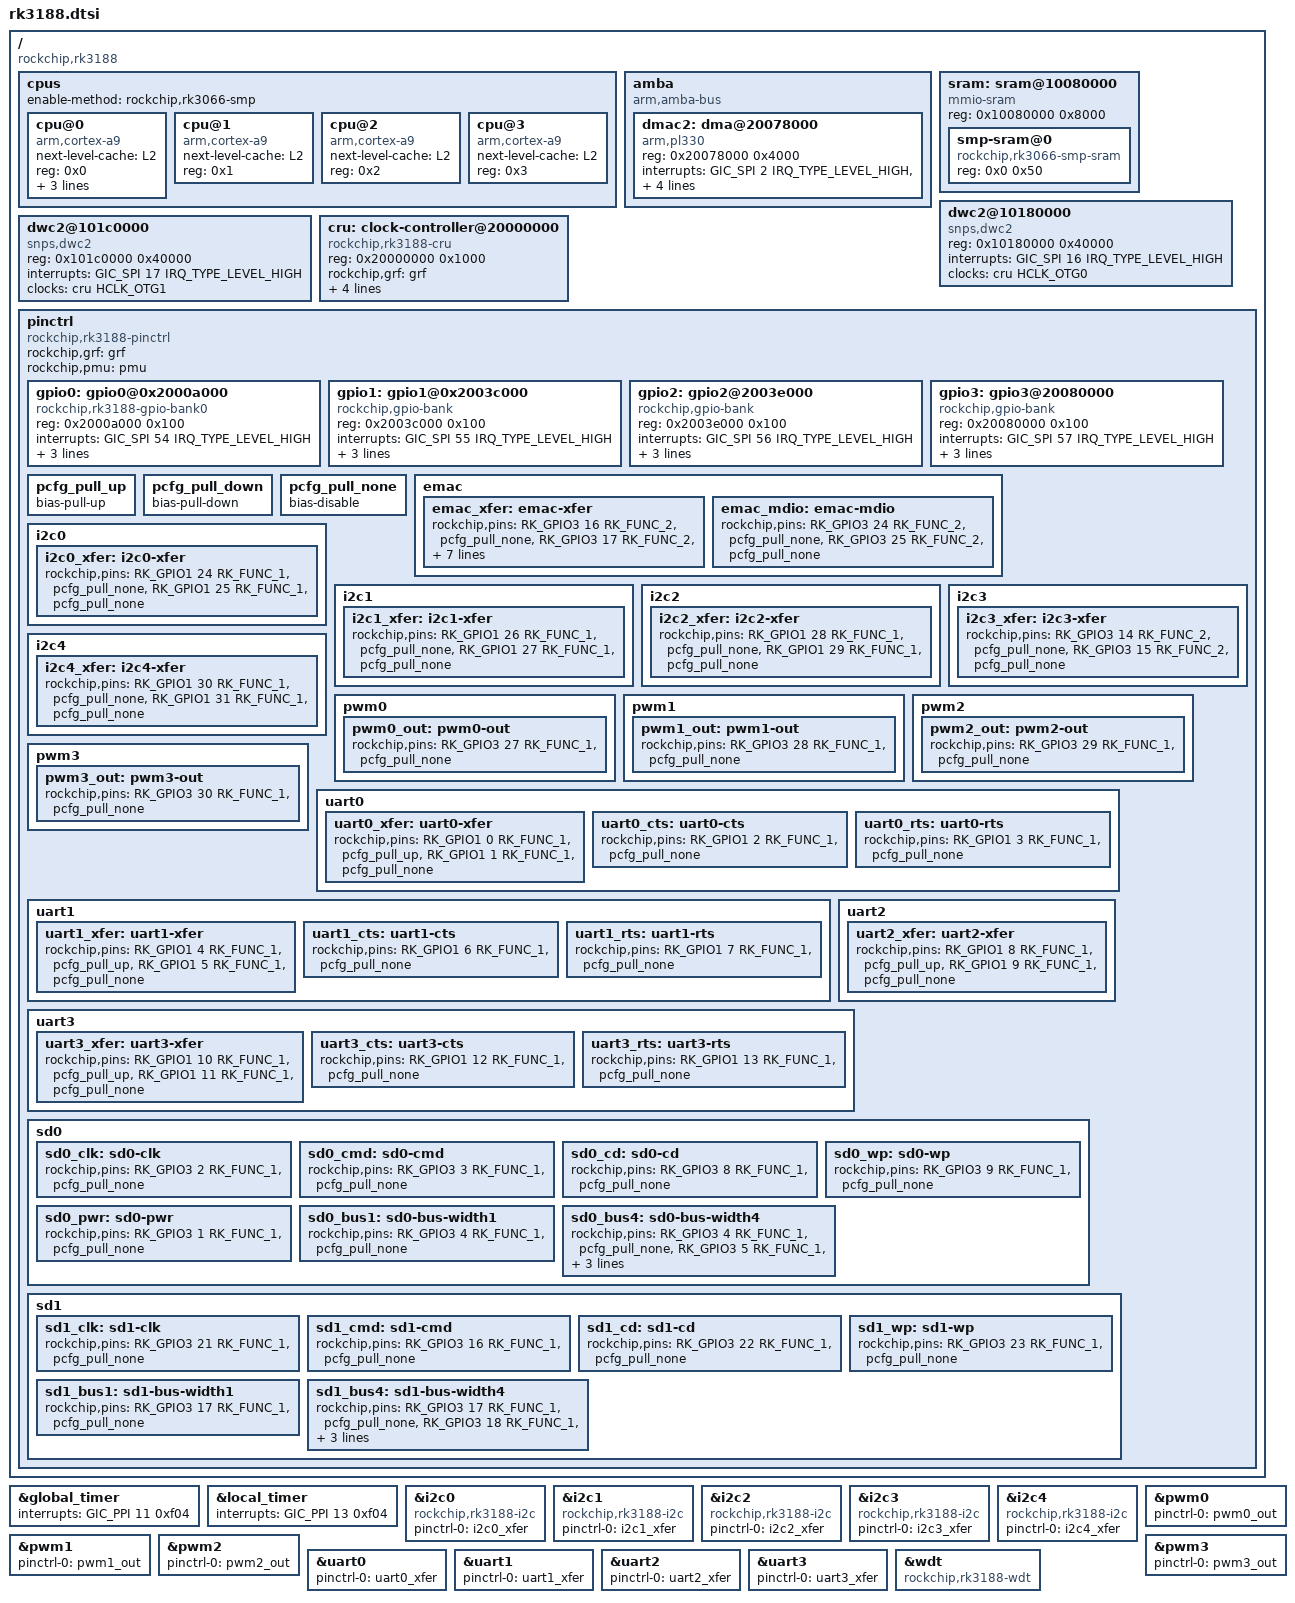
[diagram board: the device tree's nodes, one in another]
/*
 * Copyright (c) 2013 MundoReader S.L.
 * Author: Heiko Stuebner <heiko@sntech.de>
 *
 * This program is free software; you can redistribute it and/or modify
 * it under the terms of the GNU General Public License as published by
 * the Free Software Foundation; either version 2 of the License, or
 * (at your option) any later version.
 *
 * This program is distributed in the hope that it will be useful,
 * but WITHOUT ANY WARRANTY; without even the implied warranty of
 * MERCHANTABILITY or FITNESS FOR A PARTICULAR PURPOSE.  See the
 * GNU General Public License for more details.
 */

#include <dt-bindings/gpio/gpio.h>
#include <dt-bindings/pinctrl/rockchip.h>
#include <dt-bindings/clock/rk3188-cru.h>
#include "rk3xxx.dtsi"

/ {
	compatible = "rockchip,rk3188";

	cpus {
		#address-cells = <1>;
		#size-cells = <0>;
		enable-method = "rockchip,rk3066-smp";

		cpu@0 {
			device_type = "cpu";
			compatible = "arm,cortex-a9";
			next-level-cache = <&L2>;
			reg = <0x0>;
			operating-points = <
				/* kHz    uV */
				1608000 1300000
				1416000 1250000
				1200000 1150000
				1008000 1075000
				816000 975000
				600000 950000
				504000 925000
				312000 875000
			>;
			clock-latency = <40000>;
//			clocks = <&cru ARMCLK>;
		};
		cpu@1 {
			device_type = "cpu";
			compatible = "arm,cortex-a9";
			next-level-cache = <&L2>;
			reg = <0x1>;
		};
		cpu@2 {
			device_type = "cpu";
			compatible = "arm,cortex-a9";
			next-level-cache = <&L2>;
			reg = <0x2>;
		};
		cpu@3 {
			device_type = "cpu";
			compatible = "arm,cortex-a9";
			next-level-cache = <&L2>;
			reg = <0x3>;
		};
	};

	amba {
		compatible = "arm,amba-bus";
		#address-cells = <1>;
		#size-cells = <1>;
		ranges;
/*
		dmac1: dma@20018000 {
			compatible = "arm,pl330", "arm,primecell";
			reg = <0x2001c000 0x4000>;
			interrupts = <GIC_SPI 0 IRQ_TYPE_LEVEL_HIGH>,
				     <GIC_SPI 1 IRQ_TYPE_LEVEL_HIGH>;
			#dma-cells = <1>;
			#dma-channels = <7>;
			#dma-requests = <14>;
			clocks = <&cru ACLK_DMAC0>;
			clock-names = "apb_pclk";
		};*/

		dmac2: dma@20078000 {
			compatible = "arm,pl330", "arm,primecell";
			reg = <0x20078000 0x4000>;
			interrupts = <GIC_SPI 2 IRQ_TYPE_LEVEL_HIGH>,
				     <GIC_SPI 3 IRQ_TYPE_LEVEL_HIGH>;
			#dma-cells = <1>;
			#dma-channels = <7>;
			#dma-requests = <14>;
			clocks = <&cru ACLK_DMA2>;
			clock-names = "apb_pclk";
		};
	};

	sram: sram@10080000 {
		compatible = "mmio-sram";
		reg = <0x10080000 0x8000>;
		#address-cells = <1>;
		#size-cells = <1>;
		ranges = <0 0x10080000 0x8000>;

		smp-sram@0 {
			compatible = "rockchip,rk3066-smp-sram";
			reg = <0x0 0x50>;
		};
	};

	dwc2@10180000 {
		compatible = "snps,dwc2";
		reg = <0x10180000 0x40000>;
		interrupts = <GIC_SPI 16 IRQ_TYPE_LEVEL_HIGH>;
		clocks = <&cru HCLK_OTG0>;
		clock-names = "otg";
//		phys = <&usbphy0>;
//		phy-names = "usb2-phy";
	};

	dwc2@101c0000 {
		compatible = "snps,dwc2";
		reg = <0x101c0000 0x40000>;
		interrupts = <GIC_SPI 17 IRQ_TYPE_LEVEL_HIGH>;
		clocks = <&cru HCLK_OTG1>;
		clock-names = "otg";
//		phys = <&usbphy1>;
//		phy-names = "usb2-phy";
	};

	cru: clock-controller@20000000 {
		compatible = "rockchip,rk3188-cru";
		reg = <0x20000000 0x1000>;
		rockchip,grf = <&grf>;

		#clock-cells = <1>;
		#reset-cells = <1>;

		#rockchip,armclk-cells = <3>;
		rockchip,armclk-divider-table = 
/*						<2208000 2 4>,
						<2184000 2 4>,
						<2160000 2 4>,
						<2136000 2 4>,
						<2112000 2 4>,
						<2088000 2 4>,
						<2064000 2 4>,
						<2040000 2 4>,
						<2016000 2 4>,
						<1992000 2 4>,
						<1968000 2 4>,
						<1944000 2 4>,
						<1920000 2 4>,
						<1896000 2 4>,
						<1872000 2 4>,
						<1848000 2 4>,
						<1824000 2 4>,
						<1800000 2 4>,
						<1776000 2 4>,
						<1752000 2 4>,
						<1728000 2 4>,
						<1704000 2 4>,
						<1680000 2 3>,
						<1656000 2 3>,
						<1632000 2 3>, */
						<1608000 2 3>,
/*						<1560000 2 3>,
						<1512000 2 3>,
						<1488000 2 3>,
						<1464000 2 3>,
						<1440000 2 3>, */
						<1416000 2 3>,
/*						<1392000 2 3>,
						<1368000 2 3>,
						<1344000 2 3>,
						<1320000 2 3>,
						<1296000 2 3>,
						<1272000 2 3>,
						<1248000 2 3>,
						<1224000 2 3>, */
						<1200000 2 3>,
/*						<1176000 2 3>,
						<1128000 2 3>,
						<1104000 2 3>, */
						<1008000 2 3>,
/*						< 912000 2 3>,
						< 888000 2 3>, */
						< 816000 2 3>,
/*						< 792000 2 3>,
						< 696000 2 3>, */
						< 600000 1 3>,
						< 504000 1 3>,
//						< 408000 1 1>,
						< 312000 0 1>;
/*						< 252000 0 1>,
						< 216000 0 1>,
						< 126000 0 0>,
						<  48000 0 0> */
	};

	pinctrl: pinctrl {
		compatible = "rockchip,rk3188-pinctrl";
		rockchip,grf = <&grf>;
		rockchip,pmu = <&pmu>;

		#address-cells = <1>;
		#size-cells = <1>;
		ranges;

		gpio0: gpio0@0x2000a000 {
			compatible = "rockchip,rk3188-gpio-bank0";
			reg = <0x2000a000 0x100>;
			interrupts = <GIC_SPI 54 IRQ_TYPE_LEVEL_HIGH>;
			clocks = <&cru PCLK_GPIO0>;

			gpio-controller;
			#gpio-cells = <2>;

			interrupt-controller;
			#interrupt-cells = <2>;
		};

		gpio1: gpio1@0x2003c000 {
			compatible = "rockchip,gpio-bank";
			reg = <0x2003c000 0x100>;
			interrupts = <GIC_SPI 55 IRQ_TYPE_LEVEL_HIGH>;
			clocks = <&cru PCLK_GPIO1>;

			gpio-controller;
			#gpio-cells = <2>;

			interrupt-controller;
			#interrupt-cells = <2>;
		};

		gpio2: gpio2@2003e000 {
			compatible = "rockchip,gpio-bank";
			reg = <0x2003e000 0x100>;
			interrupts = <GIC_SPI 56 IRQ_TYPE_LEVEL_HIGH>;
			clocks = <&cru PCLK_GPIO2>;

			gpio-controller;
			#gpio-cells = <2>;

			interrupt-controller;
			#interrupt-cells = <2>;
		};

		gpio3: gpio3@20080000 {
			compatible = "rockchip,gpio-bank";
			reg = <0x20080000 0x100>;
			interrupts = <GIC_SPI 57 IRQ_TYPE_LEVEL_HIGH>;
			clocks = <&cru PCLK_GPIO3>;

			gpio-controller;
			#gpio-cells = <2>;

			interrupt-controller;
			#interrupt-cells = <2>;
		};

		pcfg_pull_up: pcfg_pull_up {
			bias-pull-up;
		};

		pcfg_pull_down: pcfg_pull_down {
			bias-pull-down;
		};

		pcfg_pull_none: pcfg_pull_none {
			bias-disable;
		};

		emac {
			emac_xfer: emac-xfer {
				rockchip,pins = <RK_GPIO3 16 RK_FUNC_2 &pcfg_pull_none>, //tx_en
						<RK_GPIO3 17 RK_FUNC_2 &pcfg_pull_none>, //txd1
						<RK_GPIO3 18 RK_FUNC_2 &pcfg_pull_none>, //txd0
						<RK_GPIO3 19 RK_FUNC_2 &pcfg_pull_none>, //rxd0
						<RK_GPIO3 20 RK_FUNC_2 &pcfg_pull_none>, //rxd1
						<RK_GPIO3 21 RK_FUNC_2 &pcfg_pull_none>, //mac_clk
						<RK_GPIO3 22 RK_FUNC_2 &pcfg_pull_none>, //rx_err
						<RK_GPIO3 23 RK_FUNC_2 &pcfg_pull_none>; //crs_dvalid
			};

			emac_mdio: emac-mdio {
				rockchip,pins = <RK_GPIO3 24 RK_FUNC_2 &pcfg_pull_none>,
						<RK_GPIO3 25 RK_FUNC_2 &pcfg_pull_none>;
			};
		};

		i2c0 {
			i2c0_xfer: i2c0-xfer {
				rockchip,pins = <RK_GPIO1 24 RK_FUNC_1 &pcfg_pull_none>,
						<RK_GPIO1 25 RK_FUNC_1 &pcfg_pull_none>;
			};
		};

		i2c1 {
			i2c1_xfer: i2c1-xfer {
				rockchip,pins = <RK_GPIO1 26 RK_FUNC_1 &pcfg_pull_none>,
						<RK_GPIO1 27 RK_FUNC_1 &pcfg_pull_none>;
			};
		};

		i2c2 {
			i2c2_xfer: i2c2-xfer {
				rockchip,pins = <RK_GPIO1 28 RK_FUNC_1 &pcfg_pull_none>,
						<RK_GPIO1 29 RK_FUNC_1 &pcfg_pull_none>;
			};
		};

		i2c3 {
			i2c3_xfer: i2c3-xfer {
				rockchip,pins = <RK_GPIO3 14 RK_FUNC_2 &pcfg_pull_none>,
						<RK_GPIO3 15 RK_FUNC_2 &pcfg_pull_none>;
			};
		};

		i2c4 {
			i2c4_xfer: i2c4-xfer {
				rockchip,pins = <RK_GPIO1 30 RK_FUNC_1 &pcfg_pull_none>,
						<RK_GPIO1 31 RK_FUNC_1 &pcfg_pull_none>;
			};
		};

		pwm0 {
			pwm0_out: pwm0-out {
				rockchip,pins = <RK_GPIO3 27 RK_FUNC_1 &pcfg_pull_none>;
			};
		};

		pwm1 {
			pwm1_out: pwm1-out {
				rockchip,pins = <RK_GPIO3 28 RK_FUNC_1 &pcfg_pull_none>;
			};
		};

		pwm2 {
			pwm2_out: pwm2-out {
				rockchip,pins = <RK_GPIO3 29 RK_FUNC_1 &pcfg_pull_none>;
			};
		};

		pwm3 {
			pwm3_out: pwm3-out {
				rockchip,pins = <RK_GPIO3 30 RK_FUNC_1 &pcfg_pull_none>;
			};
		};

		uart0 {
			uart0_xfer: uart0-xfer {
				rockchip,pins = <RK_GPIO1 0 RK_FUNC_1 &pcfg_pull_up>,
						<RK_GPIO1 1 RK_FUNC_1 &pcfg_pull_none>;
			};

			uart0_cts: uart0-cts {
				rockchip,pins = <RK_GPIO1 2 RK_FUNC_1 &pcfg_pull_none>;
			};

			uart0_rts: uart0-rts {
				rockchip,pins = <RK_GPIO1 3 RK_FUNC_1 &pcfg_pull_none>;
			};
		};

		uart1 {
			uart1_xfer: uart1-xfer {
				rockchip,pins = <RK_GPIO1 4 RK_FUNC_1 &pcfg_pull_up>,
						<RK_GPIO1 5 RK_FUNC_1 &pcfg_pull_none>;
			};

			uart1_cts: uart1-cts {
				rockchip,pins = <RK_GPIO1 6 RK_FUNC_1 &pcfg_pull_none>;
			};

			uart1_rts: uart1-rts {
				rockchip,pins = <RK_GPIO1 7 RK_FUNC_1 &pcfg_pull_none>;
			};
		};

		uart2 {
			uart2_xfer: uart2-xfer {
				rockchip,pins = <RK_GPIO1 8 RK_FUNC_1 &pcfg_pull_up>,
						<RK_GPIO1 9 RK_FUNC_1 &pcfg_pull_none>;
			};
			/* no rts / cts for uart2 */
		};

		uart3 {
			uart3_xfer: uart3-xfer {
				rockchip,pins = <RK_GPIO1 10 RK_FUNC_1 &pcfg_pull_up>,
						<RK_GPIO1 11 RK_FUNC_1 &pcfg_pull_none>;
			};

			uart3_cts: uart3-cts {
				rockchip,pins = <RK_GPIO1 12 RK_FUNC_1 &pcfg_pull_none>;
			};

			uart3_rts: uart3-rts {
				rockchip,pins = <RK_GPIO1 13 RK_FUNC_1 &pcfg_pull_none>;
			};
		};

		sd0 {
			sd0_clk: sd0-clk {
				rockchip,pins = <RK_GPIO3 2 RK_FUNC_1 &pcfg_pull_none>;
			};

			sd0_cmd: sd0-cmd {
				rockchip,pins = <RK_GPIO3 3 RK_FUNC_1 &pcfg_pull_none>;
			};

			sd0_cd: sd0-cd {
				rockchip,pins = <RK_GPIO3 8 RK_FUNC_1 &pcfg_pull_none>;
			};

			sd0_wp: sd0-wp {
				rockchip,pins = <RK_GPIO3 9 RK_FUNC_1 &pcfg_pull_none>;
			};

			sd0_pwr: sd0-pwr {
				rockchip,pins = <RK_GPIO3 1 RK_FUNC_1 &pcfg_pull_none>;
			};

			sd0_bus1: sd0-bus-width1 {
				rockchip,pins = <RK_GPIO3 4 RK_FUNC_1 &pcfg_pull_none>;
			};

			sd0_bus4: sd0-bus-width4 {
				rockchip,pins = <RK_GPIO3 4 RK_FUNC_1 &pcfg_pull_none>,
						<RK_GPIO3 5 RK_FUNC_1 &pcfg_pull_none>,
						<RK_GPIO3 6 RK_FUNC_1 &pcfg_pull_none>,
						<RK_GPIO3 7 RK_FUNC_1 &pcfg_pull_none>;
			};
		};

		sd1 {
			sd1_clk: sd1-clk {
				rockchip,pins = <RK_GPIO3 21 RK_FUNC_1 &pcfg_pull_none>;
			};

			sd1_cmd: sd1-cmd {
				rockchip,pins = <RK_GPIO3 16 RK_FUNC_1 &pcfg_pull_none>;
			};

			sd1_cd: sd1-cd {
				rockchip,pins = <RK_GPIO3 22 RK_FUNC_1 &pcfg_pull_none>;
			};

			sd1_wp: sd1-wp {
				rockchip,pins = <RK_GPIO3 23 RK_FUNC_1 &pcfg_pull_none>;
			};

			sd1_bus1: sd1-bus-width1 {
				rockchip,pins = <RK_GPIO3 17 RK_FUNC_1 &pcfg_pull_none>;
			};

			sd1_bus4: sd1-bus-width4 {
				rockchip,pins = <RK_GPIO3 17 RK_FUNC_1 &pcfg_pull_none>,
						<RK_GPIO3 18 RK_FUNC_1 &pcfg_pull_none>,
						<RK_GPIO3 19 RK_FUNC_1 &pcfg_pull_none>,
						<RK_GPIO3 20 RK_FUNC_1 &pcfg_pull_none>;
			};
		};
	};
};

&global_timer {
	interrupts = <GIC_PPI 11 0xf04>;
};

&local_timer {
	interrupts = <GIC_PPI 13 0xf04>;
};

&i2c0 {
	compatible = "rockchip,rk3188-i2c";
	pinctrl-names = "default";
	pinctrl-0 = <&i2c0_xfer>;
};

&i2c1 {
	compatible = "rockchip,rk3188-i2c";
	pinctrl-names = "default";
	pinctrl-0 = <&i2c1_xfer>;
};

&i2c2 {
	compatible = "rockchip,rk3188-i2c";
	pinctrl-names = "default";
	pinctrl-0 = <&i2c2_xfer>;
};

&i2c3 {
	compatible = "rockchip,rk3188-i2c";
	pinctrl-names = "default";
	pinctrl-0 = <&i2c3_xfer>;
};

&i2c4 {
	compatible = "rockchip,rk3188-i2c";
	pinctrl-names = "default";
	pinctrl-0 = <&i2c4_xfer>;
};

&pwm0 {
	pinctrl-names = "default";
	pinctrl-0 = <&pwm0_out>;
};

&pwm1 {
	pinctrl-names = "default";
	pinctrl-0 = <&pwm1_out>;
};

&pwm2 {
	pinctrl-names = "default";
	pinctrl-0 = <&pwm2_out>;
};

&pwm3 {
	pinctrl-names = "default";
	pinctrl-0 = <&pwm3_out>;
};

&uart0 {
	pinctrl-names = "default";
	pinctrl-0 = <&uart0_xfer>;
};

&uart1 {
	pinctrl-names = "default";
	pinctrl-0 = <&uart1_xfer>;
};

&uart2 {
	pinctrl-names = "default";
	pinctrl-0 = <&uart2_xfer>;
};

&uart3 {
	pinctrl-names = "default";
	pinctrl-0 = <&uart3_xfer>;
};

&wdt {
	compatible = "rockchip,rk3188-wdt", "snps,dw-wdt";
};
